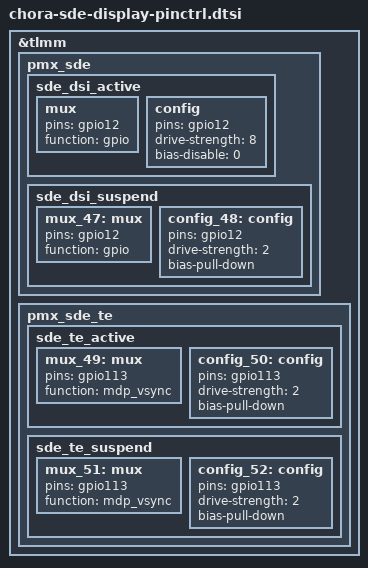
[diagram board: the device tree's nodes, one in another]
// SPDX-License-Identifier: BSD-3-Clause
/*
 * Copyright (c) Qualcomm Technologies, Inc. and/or its subsidiaries.
 */

&tlmm {
	pmx_sde: pmx_sde {
		sde_dsi_active: sde_dsi_active {
			mux: mux {
				pins = "gpio12";
				function = "gpio";
			};

			config: config {
				pins = "gpio12";
				drive-strength = <8>;   /* 8 mA */
				bias-disable = <0>;   /* no pull */
			};
		};

		sde_dsi_suspend: sde_dsi_suspend {
			mux_47: mux {
				pins = "gpio12";
				function = "gpio";
			};

			config_48: config {
				pins = "gpio12";
				drive-strength = <2>;   /* 2 mA */
				bias-pull-down;         /* PULL DOWN */
			};
		};
	};

	pmx_sde_te: pmx_sde_te {
		sde_te_active: sde_te_active {
			mux_49: mux {
				pins = "gpio113";
				function = "mdp_vsync";
			};

			config_50: config {
				pins = "gpio113";
				drive-strength = <2>;   /* 2 mA */
				bias-pull-down;         /* PULL DOWN */
			};
		};

		sde_te_suspend: sde_te_suspend {
			mux_51: mux {
				pins = "gpio113";
				function = "mdp_vsync";
			};

			config_52: config {
				pins = "gpio113";
				drive-strength = <2>;   /* 2 mA */
				bias-pull-down;         /* PULL DOWN */
			};
		};
	};
};
